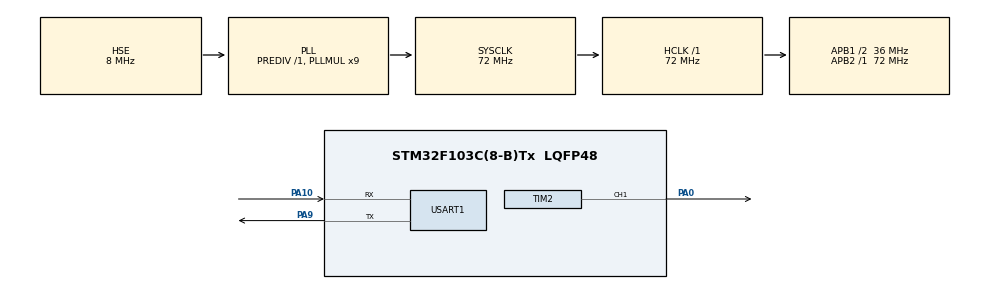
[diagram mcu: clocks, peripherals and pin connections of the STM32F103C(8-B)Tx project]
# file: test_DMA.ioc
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Dma.Request0=USART1_RX
Dma.Request1=USART1_TX
Dma.USART1_RX.0.Direction=DMA_PERIPH_TO_MEMORY
Dma.USART1_RX.0.Instance=DMA1_Channel5
Dma.USART1_RX.0.MemDataAlignment=DMA_MDATAALIGN_BYTE
Dma.USART1_RX.0.MemInc=DMA_MINC_ENABLE
Dma.USART1_RX.0.Mode=DMA_NORMAL
Dma.USART1_RX.0.PeriphDataAlignment=DMA_PDATAALIGN_BYTE
Dma.USART1_RX.0.PeriphInc=DMA_PINC_DISABLE
Dma.USART1_RX.0.Priority=DMA_PRIORITY_LOW
Dma.USART1_TX.1.Direction=DMA_MEMORY_TO_PERIPH
Dma.USART1_TX.1.Instance=DMA1_Channel4
Dma.USART1_TX.1.MemDataAlignment=DMA_MDATAALIGN_BYTE
Dma.USART1_TX.1.MemInc=DMA_MINC_ENABLE
Dma.USART1_TX.1.Mode=DMA_NORMAL
Dma.USART1_TX.1.PeriphDataAlignment=DMA_PDATAALIGN_BYTE
Dma.USART1_TX.1.PeriphInc=DMA_PINC_DISABLE
Dma.USART1_TX.1.Priority=DMA_PRIORITY_LOW
Mcu.Family=STM32F1
Mcu.Name=STM32F103C(8-B)Tx
Mcu.Package=LQFP48
NVIC.DMA1_Channel4_IRQn=true\:0\:0\:false\:false\:true\:false\:true\:true
NVIC.DMA1_Channel5_IRQn=true\:0\:0\:false\:false\:true\:false\:true\:true
NVIC.PriorityGroup=NVIC_PRIORITYGROUP_4
NVIC.USART1_IRQn=true\:0\:0\:false\:false\:true\:true\:true\:true
PA0-WKUP.GPIO_ModeDefaultPP=GPIO_MODE_AF_OD
PA0-WKUP.GPIO_Speed=GPIO_SPEED_FREQ_HIGH
PA0-WKUP.Signal=S_TIM2_CH1_ETR
PA10.Mode=Asynchronous
PA10.Signal=USART1_RX
PA13.Mode=Serial_Wire
PA13.Signal=SYS_JTMS-SWDIO
PA14.Mode=Serial_Wire
PA14.Signal=SYS_JTCK-SWCLK
PA9.Mode=Asynchronous
PA9.Signal=USART1_TX
PD0-OSC_IN.Mode=HSE-External-Oscillator
PD0-OSC_IN.Signal=RCC_OSC_IN
PD1-OSC_OUT.Mode=HSE-External-Oscillator
PD1-OSC_OUT.Signal=RCC_OSC_OUT
ProjectManager.HeapSize=0x200
ProjectManager.StackSize=0x400
ProjectManager.TargetToolchain=CMake
RCC.AHBFreq_Value=72000000
RCC.APB1CLKDivider=RCC_HCLK_DIV2
RCC.APB1Freq_Value=36000000
RCC.APB1TimFreq_Value=72000000
RCC.APB2Freq_Value=72000000
RCC.APB2TimFreq_Value=72000000
RCC.HCLKFreq_Value=72000000
RCC.PLLMUL=RCC_PLL_MUL9
RCC.PLLSourceVirtual=RCC_PLLSOURCE_HSE
RCC.SYSCLKFreq_VALUE=72000000
RCC.SYSCLKSource=RCC_SYSCLKSOURCE_PLLCLK
RCC.USBFreq_Value=72000000
SH.S_TIM2_CH1_ETR.0=TIM2_CH1,PWM Generation1 CH1
TIM2.AutoReloadPreload=TIM_AUTORELOAD_PRELOAD_ENABLE
TIM2.Channel-PWM\ Generation1\ CH1=TIM_CHANNEL_1
TIM2.Period=2000-1
TIM2.Prescaler=720-1
TIM2.Pulse-PWM\ Generation1\ CH1=50
USART1.VirtualMode=VM_ASYNC
board=custom

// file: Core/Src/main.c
/* USER CODE BEGIN Header */
/**
  ******************************************************************************
  * @file           : main.c
  * @brief          : Main program body
  ******************************************************************************
  * @attention
  *
  * Copyright (c) 2025 STMicroelectronics.
  * All rights reserved.
  *
  * This software is licensed under terms that can be found in the LICENSE file
  * in the root directory of this software component.
  * If no LICENSE file comes with this software, it is provided AS-IS.
  *
  ******************************************************************************
  */
/* USER CODE END Header */
#include "main.h"
#include "dma.h"
#include "tim.h"
#include "usart.h"
#include "gpio.h"

/* USER CODE BEGIN Includes */
#include<stdint.h>
#include<math.h>
/* USER CODE END Includes */

/* USER CODE BEGIN PD */
uint8_t uart_rx_buffer[128];
uint32_t last_receive_time =0;
uint16_t datalength =0;
volatile uint8_t uart_rx_flag=0;
/* USER CODE END PD */

/* USER CODE BEGIN PV */
uint8_t receivedata[32];
volatile uint8_t uart_idle_flag = 0;
volatile uint16_t uart_data_size = 0;
/* USER CODE END PV */

void SystemClock_Config(void);
/* USER CODE BEGIN PFP */
// void uart_dma_receive_start(void);
// void uart_check_timeout(void);
// void process_uart_data(void);
void set_servo_angle (int angle);
/* USER CODE END PFP */

/* USER CODE BEGIN 0 */
uint8_t receivedata[32];
int angle_raw=0;
 void HAL_UARTx_RxEventCallback(UART_HandleTypeDef *huart, uint16_t Size){
   if(huart ->Instance == USART1){
    angle_raw =0;
    HAL_UART_Transmit_DMA(&huart1,"hello\n",sizeof("hello"));
  for (int i=0; i < Size; i++){
      angle_raw += (int)powf(10,Size -1-i)*(receivedata[i]-'0');
    }
    HAL_UART_Transmit_DMA(&huart1,receivedata,Size);

   }
   HAL_UARTEx_ReceiveToIdle_DMA(&huart1,receivedata,sizeof(receivedata));
  set_servo_angle(angle_raw);
   }
/* USER CODE END 0 */

int main(void)
{

  /* MCU Configuration--------------------------------------------------------*/

  /* Reset of all peripherals, Initializes the Flash interface and the Systick. */
  HAL_Init();

  /* Configure the system clock */
  SystemClock_Config();

  /* Initialize all configured peripherals */
  MX_GPIO_Init();
  MX_DMA_Init();
  MX_TIM2_Init();
  MX_USART1_UART_Init();
  /* USER CODE BEGIN 2 */
  HAL_TIM_PWM_Start(&htim2,TIM_CHANNEL_1);
  HAL_UARTEx_ReceiveToIdle_DMA(&huart1,receivedata,sizeof(receivedata));
  __HAL_UART_ENABLE_IT(&huart1,UART_IT_IDLE);
  HAL_UART_Receive_DMA(&huart1,receivedata,sizeof(receivedata));
  /* USER CODE END 2 */

  /* Infinite loop */
  while (1)
  {
   HAL_Delay(500);
    __HAL_TIM_SetCompare(&htim2,TIM_CHANNEL_1,50);
    HAL_Delay(500);
    __HAL_TIM_SetCompare(&htim2,TIM_CHANNEL_1,150);
    HAL_Delay(500);
    set_servo_angle(90);
  }
}

void SystemClock_Config(void)
{
  RCC_OscInitTypeDef RCC_OscInitStruct = {0};
  RCC_ClkInitTypeDef RCC_ClkInitStruct = {0};

  /** Initializes the RCC Oscillators according to the specified parameters
  * in the RCC_OscInitTypeDef structure.
  */
  RCC_OscInitStruct.OscillatorType = RCC_OSCILLATORTYPE_HSE;
  RCC_OscInitStruct.HSEState = RCC_HSE_ON;
  RCC_OscInitStruct.HSEPredivValue = RCC_HSE_PREDIV_DIV1;
  RCC_OscInitStruct.HSIState = RCC_HSI_ON;
  RCC_OscInitStruct.PLL.PLLState = RCC_PLL_ON;
  RCC_OscInitStruct.PLL.PLLSource = RCC_PLLSOURCE_HSE;
  RCC_OscInitStruct.PLL.PLLMUL = RCC_PLL_MUL9;
  if (HAL_RCC_OscConfig(&RCC_OscInitStruct) != HAL_OK)
  {
    Error_Handler();
  }

  /** Initializes the CPU, AHB and APB buses clocks
  */
  RCC_ClkInitStruct.ClockType = RCC_CLOCKTYPE_HCLK|RCC_CLOCKTYPE_SYSCLK
                              |RCC_CLOCKTYPE_PCLK1|RCC_CLOCKTYPE_PCLK2;
  RCC_ClkInitStruct.SYSCLKSource = RCC_SYSCLKSOURCE_PLLCLK;
  RCC_ClkInitStruct.AHBCLKDivider = RCC_SYSCLK_DIV1;
  RCC_ClkInitStruct.APB1CLKDivider = RCC_HCLK_DIV2;
  RCC_ClkInitStruct.APB2CLKDivider = RCC_HCLK_DIV1;

  if (HAL_RCC_ClockConfig(&RCC_ClkInitStruct, FLASH_LATENCY_2) != HAL_OK)
  {
    Error_Handler();
  }
}

/* USER CODE BEGIN 4 */
void set_servo_angle(int angle){
  if (angle < 0){
    angle=0;
  }
  if(angle >180){
    angle=180;
  }
  uint32_t pulse_width =500+angle*2000/180;
  uint32_t ccr_value = (pulse_width*(19999+1))/20000;
  __HAL_TIM_SetCompare(&htim2,TIM_CHANNEL_1,ccr_value);
}
// void uart_dma_receive_start(void){
//   HAL_UART_Receive_DMA(&huart1,uart_rx_buffer,sizeof(uart_rx_buffer));
// }
// uint16_t uart_get_receive_length(void){
//   return sizeof(uart_rx_buffer)-__HAL_DMA_GET_COUNTER(&hdma_usart1_rx)
// }

/* USER CODE END 4 */

void Error_Handler(void)
{
  __disable_irq();
  while (1)
  {
  }
}
